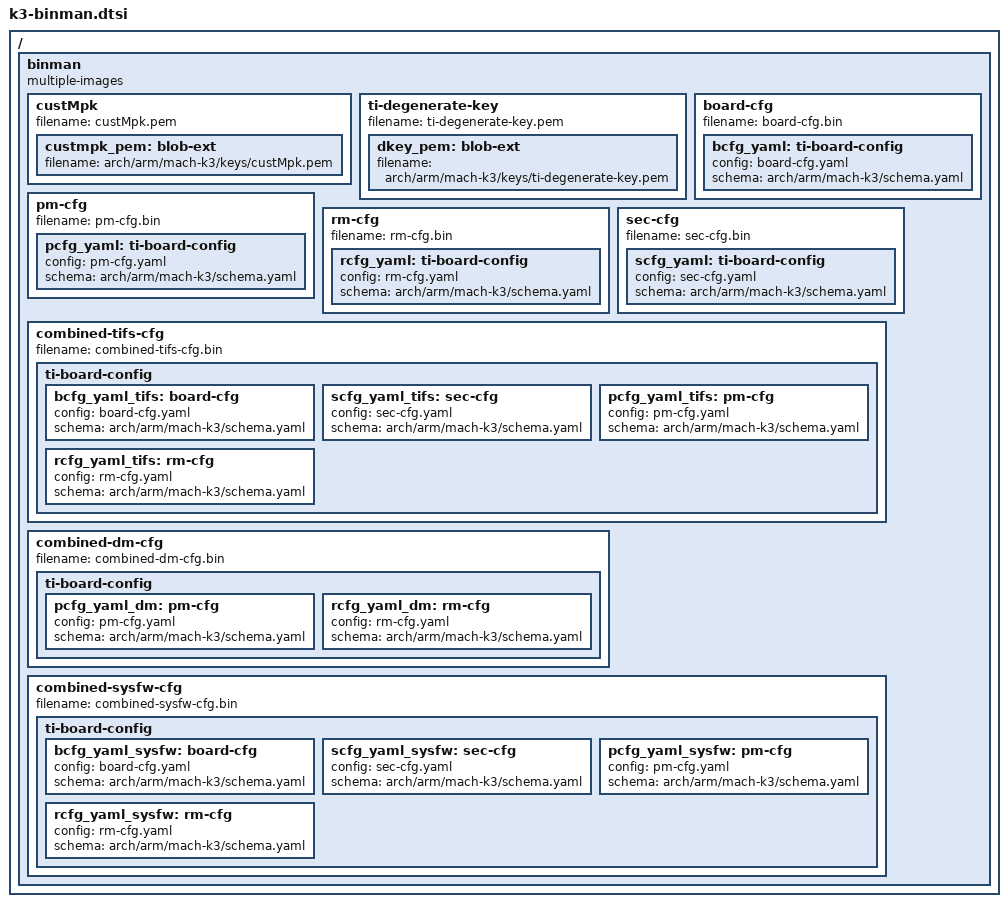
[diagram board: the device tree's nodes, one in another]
// SPDX-License-Identifier: GPL-2.0
/*
 * Copyright (C) 2022-2023 Texas Instruments Incorporated - https://www.ti.com/
 */

/ {
	binman: binman {
		multiple-images;
	};
};

&binman {
	custMpk {
		filename = "custMpk.pem";
		custmpk_pem: blob-ext {
			filename = "arch/arm/mach-k3/keys/custMpk.pem";
		};
	};

	ti-degenerate-key {
		filename = "ti-degenerate-key.pem";
		dkey_pem: blob-ext {
			filename = "arch/arm/mach-k3/keys/ti-degenerate-key.pem";
		};
	};
};

#ifndef CONFIG_ARM64

&binman {
	board-cfg {
		filename = "board-cfg.bin";
		bcfg_yaml: ti-board-config {
			config = "board-cfg.yaml";
			schema = "arch/arm/mach-k3/schema.yaml";
		};
	};
	pm-cfg {
		filename = "pm-cfg.bin";
		pcfg_yaml: ti-board-config {
			config = "pm-cfg.yaml";
			schema = "arch/arm/mach-k3/schema.yaml";
		};
	};
	rm-cfg {
		filename = "rm-cfg.bin";
		rcfg_yaml: ti-board-config {
			config = "rm-cfg.yaml";
			schema = "arch/arm/mach-k3/schema.yaml";
		};
	};
	sec-cfg {
		filename = "sec-cfg.bin";
		scfg_yaml: ti-board-config {
			config = "sec-cfg.yaml";
			schema = "arch/arm/mach-k3/schema.yaml";
		};
	};
	combined-tifs-cfg {
		filename = "combined-tifs-cfg.bin";
		ti-board-config {
			bcfg_yaml_tifs: board-cfg {
				config = "board-cfg.yaml";
				schema = "arch/arm/mach-k3/schema.yaml";
			};
			scfg_yaml_tifs: sec-cfg {
				config = "sec-cfg.yaml";
				schema = "arch/arm/mach-k3/schema.yaml";
			};
			pcfg_yaml_tifs: pm-cfg {
				config = "pm-cfg.yaml";
				schema = "arch/arm/mach-k3/schema.yaml";
			};
			rcfg_yaml_tifs: rm-cfg {
				config = "rm-cfg.yaml";
				schema = "arch/arm/mach-k3/schema.yaml";
			};
		};
	};
	combined-dm-cfg {
		filename = "combined-dm-cfg.bin";
		ti-board-config {
			pcfg_yaml_dm: pm-cfg {
				config = "pm-cfg.yaml";
				schema = "arch/arm/mach-k3/schema.yaml";
			};
			rcfg_yaml_dm: rm-cfg {
				config = "rm-cfg.yaml";
				schema = "arch/arm/mach-k3/schema.yaml";
			};
		};
	};
	combined-sysfw-cfg {
		filename = "combined-sysfw-cfg.bin";
		ti-board-config {
			bcfg_yaml_sysfw: board-cfg {
				config = "board-cfg.yaml";
				schema = "arch/arm/mach-k3/schema.yaml";
			};
			scfg_yaml_sysfw: sec-cfg {
				config = "sec-cfg.yaml";
				schema = "arch/arm/mach-k3/schema.yaml";
			};
			pcfg_yaml_sysfw: pm-cfg {
				config = "pm-cfg.yaml";
				schema = "arch/arm/mach-k3/schema.yaml";
			};
			rcfg_yaml_sysfw: rm-cfg {
				config = "rm-cfg.yaml";
				schema = "arch/arm/mach-k3/schema.yaml";
			};
		};
	};
};

#endif
